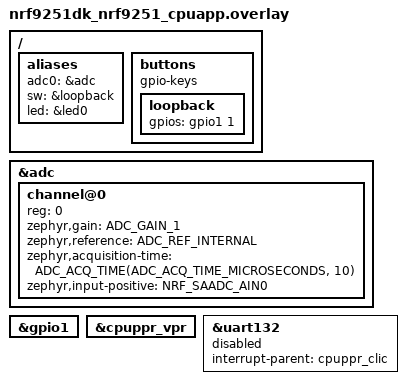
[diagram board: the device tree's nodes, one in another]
/*
 * Copyright (c) 2026 Nordic Semiconductor ASA
 *
 * SPDX-License-Identifier: LicenseRef-Nordic-5-Clause
 */

/* Required GPIO loopback: P1.00 - P1.01 */

/ {
	aliases {
		adc0 = &adc;
		sw = &loopback;
		led = &led0;
	};

	buttons {
		compatible = "gpio-keys";

		loopback: loopback {
			gpios = <&gpio1 1 GPIO_ACTIVE_HIGH>;
		};
	};
};

&adc {
	#address-cells = <1>;
	#size-cells = <0>;

	channel@0 {
		reg = <0>;
		zephyr,gain = "ADC_GAIN_1";
		zephyr,reference = "ADC_REF_INTERNAL";
		zephyr,acquisition-time = <ADC_ACQ_TIME(ADC_ACQ_TIME_MICROSECONDS, 10)>;
		zephyr,input-positive = <NRF_SAADC_AIN0>;
	};
};

&gpio1 {
	status = "okay";
};

&cpuppr_vpr {
	status = "okay";
};

&uart132 {
	status = "reserved";
	interrupt-parent = <&cpuppr_clic>;
};
